# CS__Clock_System_4 register map
Vendor: Texas Instruments
Peripheral module from a debugger description file (folder msp430).
Registers are 8-bit, read-write, reset 0x0 unless marked. A register's access mark holds for its fields unless they carry their own. Offsets are as the file gives them; lines under a group give offsets from that group; [hi:lo] are bit positions; {n}, {i} and the like mark numbered series; 'fields as' and 'values as' point back to an identical list; <NAME> marks a mode.

## CS_Clock_System
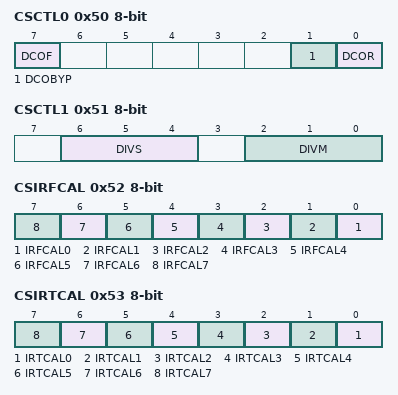
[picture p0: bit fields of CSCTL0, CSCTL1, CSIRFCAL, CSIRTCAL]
0x50 CSCTL0 — CS Control Register 0
  [7] DCOF — DCO fault flag
  [1] DCOBYP — DCO bypass mode
  [0] DCOR — DCO resistor select
0x51 CSCTL1 — CS Control Register 1
  [6:4] DIVS — SMCLK Divider Bit: 0
    {v}=SMCLK Source Divider {v} (v=0..3); {v}=SMCLK Source Divider {v+1} (v=4..7)
  [2:0] DIVM — MCLK Divider Bit: 0
    {v}=MCLK Source Divider {v} (v=0..3); {v}=MCLK Source Divider {v+1} (v=4..7)
0x52 CSIRFCAL — CS Internal Resistor Frequency Calibration
  [n] IRFCAL{n} (n=0..7) — DCO internal resistor frequency calibration value Bit {n}
0x53 CSIRTCAL — CS Internal Resistor Temperature Calibration
  [n] IRTCAL{n} (n=0..7) — DCO internal resistor temperature calibration value Bit {n}
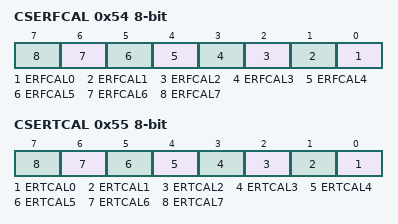
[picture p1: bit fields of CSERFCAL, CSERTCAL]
0x54 CSERFCAL — CS External Resistor Frequency Calibration
  [n] ERFCAL{n} (n=0..7) — DCO external resistor frequency calibration value Bit {n}
0x55 CSERTCAL — CS External Resistor Temperature Calibration
  [n] ERTCAL{n} (n=0..7) — DCO external resistor temperature calibration value Bit {n}
